VERSION ""

NS_ :

BS_:

BU_:

BO_ 3221225472 VECTOR__INDEPENDENT_SIG_MSG: 0 Vector__XXX
 SG_ FL_brake_temperature : 0|16@1+ (1,0) [0|0] "" Vector__XXX
 SG_ FR_brake_temperature : 16|16@1+ (1,0) [0|0] "" Vector__XXX
 SG_ RL_brake_temperature : 48|16@1+ (1,0) [0|0] "" Vector__XXX
 SG_ RR_brake_temperature : 32|16@1+ (1,0) [0|0] "" Vector__XXX
 SG_ off_grid_power_connection : 24|1@1+ (1,0) [0|0] "" Vector__XXX

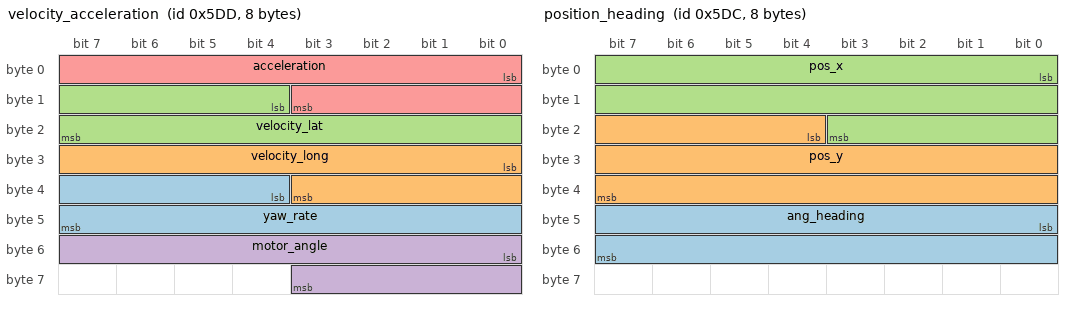
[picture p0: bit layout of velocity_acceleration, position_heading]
BO_ 1501 velocity_acceleration: 8 Vector__XXX
 SG_ yaw_rate : 36|12@1- (0.025,0) [-51.2|51.175] "rps" Vector__XXX
 SG_ velocity_long : 24|12@1- (0.05,0) [-102.4|102.35] "mps" Vector__XXX
 SG_ velocity_lat : 12|12@1- (0.05,0) [-102.4|102.35] "mps" Vector__XXX
 SG_ motor_angle : 48|12@1- (0.5,0) [-255|255] "rad" Vector__XXX
 SG_ acceleration : 0|12@1- (0.025,0) [-51.2|51.175] "mps2" Vector__XXX

BO_ 1500 position_heading: 8 Vector__XXX
 SG_ ang_heading : 40|16@1- (0.01,0) [-327.68|327.67] "rad" Vector__XXX
 SG_ pos_y : 20|20@1- (0.01,0) [-5242.88|5242.87] "m" Vector__XXX
 SG_ pos_x : 0|20@1- (0.01,0) [-5242.88|5242.87] "m" Vector__XXX

BO_ 1403 gear_shift_cmd: 8 Vector__XXX
 SG_ desired_gear : 0|8@1+ (1,0) [0|0] "" Vector__XXX

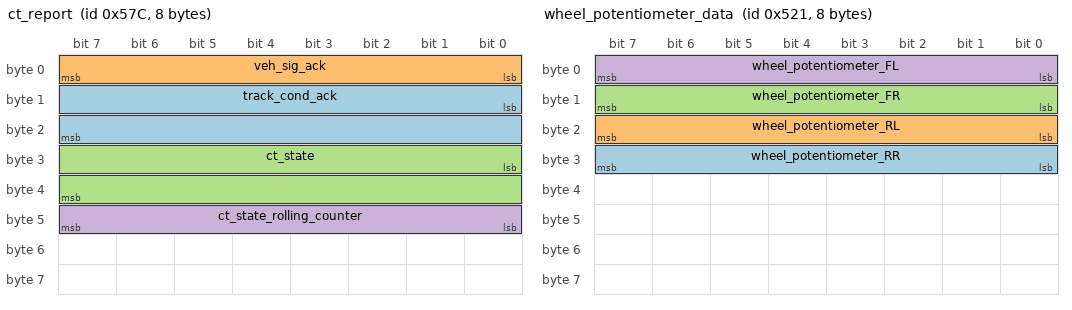
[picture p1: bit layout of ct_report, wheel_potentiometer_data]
BO_ 1404 ct_report: 8 Vector__XXX
 SG_ track_cond_ack : 8|16@1+ (1,0) [0|0] "" Vector__XXX
 SG_ veh_sig_ack : 0|8@1+ (1,0) [0|0] "" Vector__XXX
 SG_ ct_state : 24|16@1+ (1,0) [0|0] "" Vector__XXX
 SG_ ct_state_rolling_counter : 40|8@1+ (1,0) [0|9] "" Vector__XXX

BO_ 1402 steering_cmd: 8 Vector__XXX
 SG_ steering_motor_cmd_counter : 16|8@1+ (1,0) [0|255] "" Vector__XXX
 SG_ steering_motor_ang_cmd : 0|10@1- (0.5,0) [-512|511] "deg" Vector__XXX

BO_ 1401 accelerator_cmd: 8 Vector__XXX
 SG_ acc_pedal_cmd_counter : 16|8@1+ (1,0) [0|255] "" Vector__XXX
 SG_ acc_pedal_cmd : 0|16@1- (0.01,0) [-150|655.35] "%" Vector__XXX

BO_ 1400 brake_pressure_cmd: 8 Vector__XXX
 SG_ brk_pressure_cmd_counter : 16|8@1+ (1,0) [0|255] "" Vector__XXX
 SG_ brake_pressure_cmd : 0|13@1+ (1,0) [0|8191] "" Vector__XXX

BO_ 1313 wheel_potentiometer_data: 8 Vector__XXX
 SG_ wheel_potentiometer_RR : 24|8@1+ (0.2,0) [0|510] "" Vector__XXX
 SG_ wheel_potentiometer_RL : 16|8@1+ (0.2,0) [0|510] "" Vector__XXX
 SG_ wheel_potentiometer_FR : 8|8@1+ (0.2,0) [0|510] "" Vector__XXX
 SG_ wheel_potentiometer_FL : 0|8@1+ (0.2,0) [0|510] "" Vector__XXX

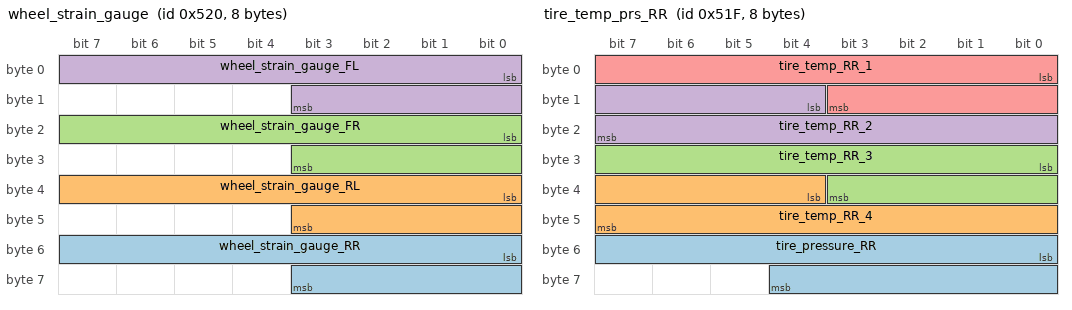
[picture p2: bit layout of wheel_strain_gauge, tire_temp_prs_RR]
BO_ 1312 wheel_strain_gauge: 8 Vector__XXX
 SG_ wheel_strain_gauge_RR : 48|12@1+ (10,0) [0|8190] "" Vector__XXX
 SG_ wheel_strain_gauge_RL : 32|12@1+ (10,0) [0|8190] "" Vector__XXX
 SG_ wheel_strain_gauge_FR : 16|12@1+ (10,0) [0|8190] "" Vector__XXX
 SG_ wheel_strain_gauge_FL : 0|12@1+ (10,0) [0|81900] "" Vector__XXX

BO_ 1311 tire_temp_prs_RR: 8 Vector__XXX
 SG_ tire_pressure_RR : 48|13@1+ (1,0) [0|8191] "C" Vector__XXX
 SG_ tire_temp_RR_4 : 36|12@1+ (0.1,-100) [-100|309.5] "C" Vector__XXX
 SG_ tire_temp_RR_3 : 24|12@1+ (0.1,-100) [-100|309.5] "C" Vector__XXX
 SG_ tire_temp_RR_2 : 12|12@1+ (0.1,-100) [-100|309.5] "C" Vector__XXX
 SG_ tire_temp_RR_1 : 0|12@1+ (0.1,-100) [-100|309.5] "mBar" Vector__XXX

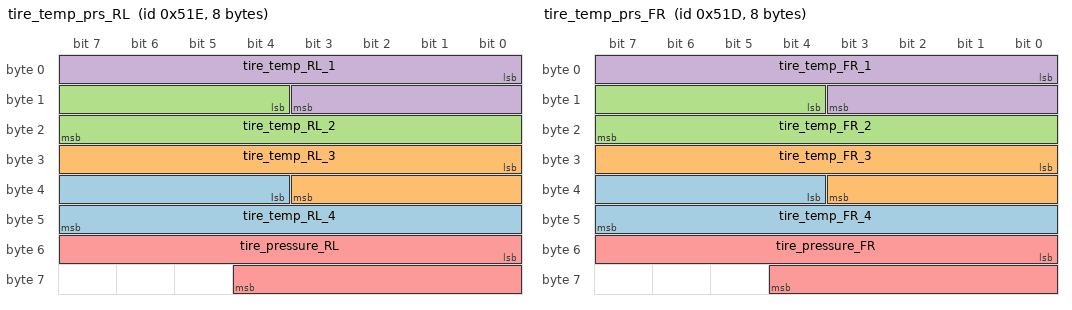
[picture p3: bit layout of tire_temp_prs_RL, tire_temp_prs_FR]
BO_ 1310 tire_temp_prs_RL: 8 Vector__XXX
 SG_ tire_temp_RL_4 : 36|12@1+ (0.1,-100) [-100|309.5] "C" Vector__XXX
 SG_ tire_temp_RL_3 : 24|12@1+ (0.1,-100) [-100|309.5] "C" Vector__XXX
 SG_ tire_temp_RL_2 : 12|12@1+ (0.1,-100) [-100|309.5] "C" Vector__XXX
 SG_ tire_temp_RL_1 : 0|12@1+ (0.1,-100) [-100|309.5] "C" Vector__XXX
 SG_ tire_pressure_RL : 48|13@1+ (1,0) [0|8191] "mBar" Vector__XXX

BO_ 1309 tire_temp_prs_FR: 8 Vector__XXX
 SG_ tire_temp_FR_4 : 36|12@1+ (0.1,-100) [-100|309.5] "C" Vector__XXX
 SG_ tire_temp_FR_3 : 24|12@1+ (0.1,-100) [-100|309.5] "C" Vector__XXX
 SG_ tire_temp_FR_2 : 12|12@1+ (0.1,-100) [-100|309.5] "C" Vector__XXX
 SG_ tire_temp_FR_1 : 0|12@1+ (0.1,-100) [-100|309.5] "C" Vector__XXX
 SG_ tire_pressure_FR : 48|13@1+ (1,0) [0|8191] "mBar" Vector__XXX

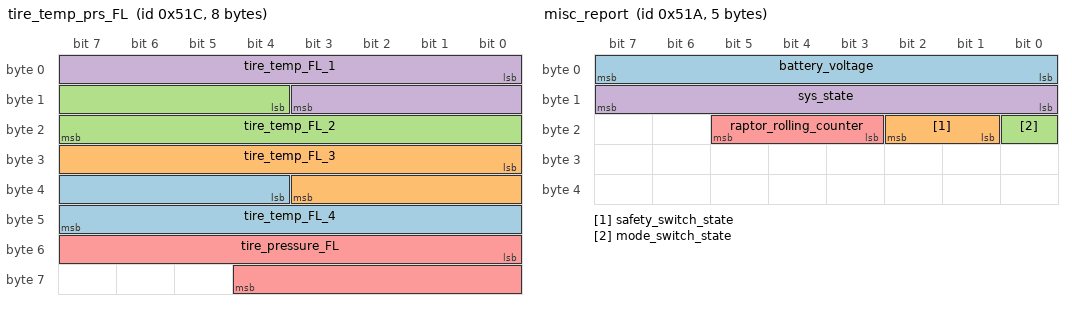
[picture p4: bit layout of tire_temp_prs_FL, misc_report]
BO_ 1308 tire_temp_prs_FL: 8 Vector__XXX
 SG_ tire_temp_FL_4 : 36|12@1+ (0.1,-100) [-100|309.5] "C" Vector__XXX
 SG_ tire_temp_FL_3 : 24|12@1+ (0.1,-100) [-100|309.5] "C" Vector__XXX
 SG_ tire_temp_FL_2 : 12|12@1+ (0.1,-100) [-100|309.5] "C" Vector__XXX
 SG_ tire_temp_FL_1 : 0|12@1+ (0.1,-100) [-100|309.5] "C" Vector__XXX
 SG_ tire_pressure_FL : 48|13@1+ (1,0) [0|8191] "mBar" Vector__XXX

BO_ 1306 misc_report: 5 Vector__XXX
 SG_ battery_voltage : 0|8@1+ (10,0) [0|0] "V" Vector__XXX
 SG_ safety_switch_state : 17|2@1+ (1,0) [0|0] "" Vector__XXX
 SG_ mode_switch_state : 16|1@1+ (1,0) [0|0] "" Vector__XXX
 SG_ sys_state : 8|8@1+ (1,0) [0|0] "" Vector__XXX
 SG_ raptor_rolling_counter : 19|3@1+ (1,0) [0|0] "" Vector__XXX

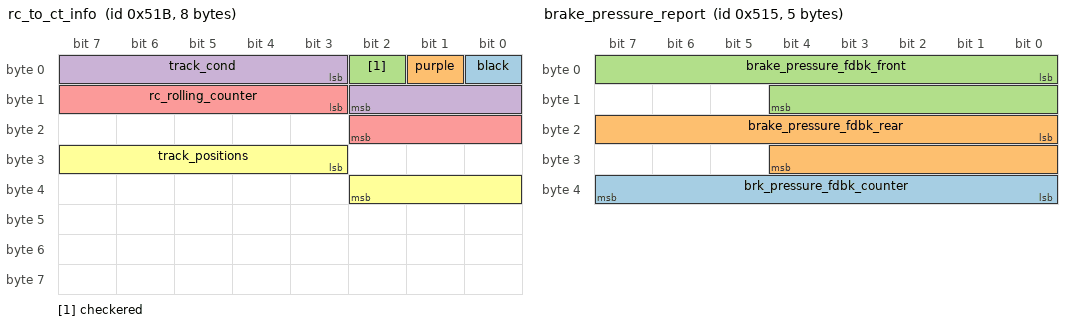
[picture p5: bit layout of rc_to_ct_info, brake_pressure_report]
BO_ 1307 rc_to_ct_info: 8 Vector__XXX
 SG_ black : 0|1@1+ (1,0) [0|0] "" Vector__XXX
 SG_ purple : 1|1@1+ (1,0) [0|0] "" Vector__XXX
 SG_ checkered : 2|1@1+ (1,0) [0|0] "" Vector__XXX
 SG_ track_cond : 3|8@1+ (1,0) [0|0] "" Vector__XXX
 SG_ rc_rolling_counter : 11|8@1+ (1,0) [0|0] "" Vector__XXX
 SG_ track_positions : 27|8@1+ (1,0) [0|0] "" Vector__XXX

BO_ 1303 steering_report: 3 Vector__XXX
 SG_ steering_motor_fdbk_counter : 16|8@1+ (1,0) [0|255] "" Vector__XXX
 SG_ steering_motor_ang_fdbk : 0|10@1- (0.5,0) [-512|511] "deg" Vector__XXX

BO_ 1302 accelerator_report: 3 Vector__XXX
 SG_ acc_pedal_fdbk_counter : 16|8@1+ (1,0) [0|255] "" Vector__XXX
 SG_ acc_pedal_fdbk : 0|16@1+ (1,0) [0|65535] "%" Vector__XXX

BO_ 1301 brake_pressure_report: 5 Vector__XXX
 SG_ brk_pressure_fdbk_counter : 32|8@1+ (1,0) [0|255] "" Vector__XXX
 SG_ brake_pressure_fdbk_rear : 16|13@1+ (1,0) [0|8191] "kPa" Vector__XXX
 SG_ brake_pressure_fdbk_front : 0|13@1+ (1,0) [0|8191] "kPa" Vector__XXX

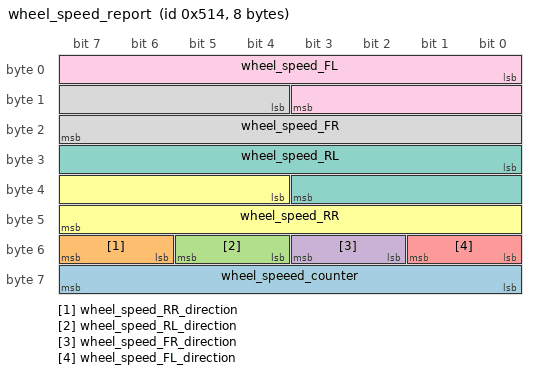
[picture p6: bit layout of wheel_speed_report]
BO_ 1300 wheel_speed_report: 8 Vector__XXX
 SG_ wheel_speeed_counter : 56|8@1+ (1,0) [0|255] "" Vector__XXX
 SG_ wheel_speed_RR_direction : 54|2@1- (1,0) [-1|1] "" Vector__XXX
 SG_ wheel_speed_RL_direction : 52|2@1- (1,0) [-1|1] "" Vector__XXX
 SG_ wheel_speed_FR_direction : 50|2@1- (1,0) [-1|1] "" Vector__XXX
 SG_ wheel_speed_FL_direction : 48|2@1- (1,0) [-1|1] "" Vector__XXX
 SG_ wheel_speed_RR : 36|12@1+ (1,0) [0|4095] "rpm" Vector__XXX
 SG_ wheel_speed_RL : 24|12@1+ (1,0) [0|4095] "rpm" Vector__XXX
 SG_ wheel_speed_FR : 12|12@1+ (1,0) [0|4095] "rpm" Vector__XXX
 SG_ wheel_speed_FL : 0|12@1+ (1,0) [0|4095] "rpm" Vector__XXX

CM_ SG_ 3221225472 off_grid_power_connection "remove it";
CM_ BO_ 1403 "DO12 - gear shift command";
CM_ BO_ 1404 "DO12 - CT report to RC";
CM_ BO_ 1402 "steering demand from computer to raptor in degrees
";
CM_ SG_ 1402 steering_motor_cmd_counter "rolling counter for steering motor angle commamd message";
CM_ SG_ 1402 steering_motor_ang_cmd "motor angle command  in deg.

physical_value = offset + factor * raw_value_decimal";
CM_ SG_ 1401 acc_pedal_cmd "0-100 % accelerator pedal
";
CM_ BO_ 1400 "Demand of brake pressure fron computer to rapter in kPa
";
CM_ SG_ 1400 brk_pressure_cmd_counter "rolling counter for brake pressure command message";
CM_ SG_ 1400 brake_pressure_cmd "Brake pressure for front wheels in kPa. demand from competition team
values should be positive integer in kPa.";
CM_ BO_ 1313 "Contains the information of potnetiometer, strain gage readings and calculated Fz of the front right wheel ";
CM_ SG_ 1313 wheel_potentiometer_RR "potentiometer reading of front left assembly";
CM_ SG_ 1313 wheel_potentiometer_RL "potentiometer reading of front left assembly";
CM_ SG_ 1313 wheel_potentiometer_FR "potentiometer reading of front left assembly";
CM_ SG_ 1313 wheel_potentiometer_FL "potentiometer reading of front left assembly";
CM_ BO_ 1312 "Contains the information of potnetiometer, strain gage readings and calculated Fz of the front left wheel ";
CM_ SG_ 1312 wheel_strain_gauge_RR "strain gauge load value in N rear right wheel  in mm.
";
CM_ SG_ 1312 wheel_strain_gauge_RL "strain gauge load value in N rear left wheel  in mm.
";
CM_ SG_ 1312 wheel_strain_gauge_FR "strain gauge load value in N front right wheel  in mm.
";
CM_ SG_ 1312 wheel_strain_gauge_FL "strain gauge load value in N front left wheel in mm.
";
CM_ BO_ 1311 "temperature and pressure information for front left tire";
CM_ SG_ 1311 tire_pressure_RR "tire pressure in mBar";
CM_ SG_ 1311 tire_temp_RR_4 "tire core temperature data will be in deg.
signal_1 : left portion of tire
signal_2 : middle left portion of tire
signal_3 : middle right portion of tire
signal_4 : right portion of tire
";
CM_ SG_ 1311 tire_temp_RR_3 "tire core temperature data will be in deg.
signal_1 : left portion of tire
signal_2 : middle left portion of tire
signal_3 : middle right portion of tire
signal_4 : right portion of tire
";
CM_ SG_ 1311 tire_temp_RR_2 "tire core temperature data will be in deg.
signal_1 : left portion of tire
signal_2 : middle left portion of tire
signal_3 : middle right portion of tire
signal_4 : right portion of tire
";
CM_ SG_ 1311 tire_temp_RR_1 "tire core temperature data will be in deg.
signal_1 : left portion of tire
signal_2 : middle left portion of tire
signal_3 : middle right portion of tire
signal_4 : right portion of tire
";
CM_ BO_ 1310 "temperature and pressure information for front left tire";
CM_ SG_ 1310 tire_temp_RL_4 "tire core temperature data will be in deg.
signal_1 : left portion of tire
signal_2 : middle left portion of tire
signal_3 : middle right portion of tire
signal_4 : right portion of tire
";
CM_ SG_ 1310 tire_temp_RL_3 "tire core temperature data will be in deg.
signal_1 : left portion of tire
signal_2 : middle left portion of tire
signal_3 : middle right portion of tire
signal_4 : right portion of tire
";
CM_ SG_ 1310 tire_temp_RL_2 "tire core temperature data will be in deg.
signal_1 : left portion of tire
signal_2 : middle left portion of tire
signal_3 : middle right portion of tire
signal_4 : right portion of tire
";
CM_ SG_ 1310 tire_temp_RL_1 "tire core temperature data will be in deg.
signal_1 : left portion of tire
signal_2 : middle left portion of tire
signal_3 : middle right portion of tire
signal_4 : right portion of tire
";
CM_ SG_ 1310 tire_pressure_RL "tire pressure in mBar";
CM_ BO_ 1309 "temperature and pressure information for front left tire";
CM_ SG_ 1309 tire_temp_FR_4 "tire core temperature data will be in deg.
signal_1 : left portion of tire
signal_2 : middle left portion of tire
signal_3 : middle right portion of tire
signal_4 : right portion of tire
";
CM_ SG_ 1309 tire_temp_FR_3 "tire core temperature data will be in deg.
signal_1 : left portion of tire
signal_2 : middle left portion of tire
signal_3 : middle right portion of tire
signal_4 : right portion of tire
";
CM_ SG_ 1309 tire_temp_FR_2 "tire core temperature data will be in deg.
signal_1 : left portion of tire
signal_2 : middle left portion of tire
signal_3 : middle right portion of tire
signal_4 : right portion of tire
";
CM_ SG_ 1309 tire_temp_FR_1 "tire core temperature data will be in deg.
signal_1 : left portion of tire
signal_2 : middle left portion of tire
signal_3 : middle right portion of tire
signal_4 : right portion of tire
";
CM_ SG_ 1309 tire_pressure_FR "tire pressure in mBar";
CM_ BO_ 1308 "temperature and pressure information for front left tire";
CM_ SG_ 1308 tire_temp_FL_4 "tire core temperature data will be in deg.
signal_1 : left portion of tire
signal_2 : middle left portion of tire
signal_3 : middle right portion of tire
signal_4 : right portion of tire
";
CM_ SG_ 1308 tire_temp_FL_3 "tire core temperature data will be in deg.
signal_1 : left portion of tire
signal_2 : middle left portion of tire
signal_3 : middle right portion of tire
signal_4 : right portion of tire
";
CM_ SG_ 1308 tire_temp_FL_2 "tire core temperature data will be in deg.
signal_1 : left portion of tire
signal_2 : middle left portion of tire
signal_3 : middle right portion of tire
signal_4 : right portion of tire
";
CM_ SG_ 1308 tire_temp_FL_1 "tire core temperature data will be in deg.
signal_1 : left portion of tire
signal_2 : middle left portion of tire
signal_3 : middle right portion of tire
signal_4 : right portion of tire
";
CM_ SG_ 1308 tire_pressure_FL "tire pressure in mBar";
CM_ BO_ 1306 "DO12 - misc report";
CM_ BO_ 1307 "TODO: Needs to be changed, inconsistent
";
CM_ SG_ 1303 steering_motor_fdbk_counter "rolling counter for steering motor angle feedbak message";
CM_ SG_ 1303 steering_motor_ang_fdbk "motor angle feedback in deg.

physical_value = offset + factor * raw_value_decimal";
CM_ BO_ 1301 "Brake pressure for front and rear wheels in kPa. ";
CM_ SG_ 1301 brk_pressure_fdbk_counter "rolling counter for brake pressure feedback message";
CM_ SG_ 1301 brake_pressure_fdbk_rear "Brake pressure for rear wheels in kPa. 
values will be positive integer in kPa.";
CM_ SG_ 1301 brake_pressure_fdbk_front "Brake pressure for front wheels in kPa. 
values will be positive integer in kPa.";
CM_ SG_ 1300 wheel_speeed_counter "rolling counter for wheel speed message";
CM_ SG_ 1300 wheel_speed_RR_direction "wheel speed of rear right:

+1: forward
  0: static
- 1: reverse";
CM_ SG_ 1300 wheel_speed_RL_direction "wheel speed of rear left:

+1: forward
  0: static
- 1: reverse";
CM_ SG_ 1300 wheel_speed_FR_direction "wheel speed of front right:

+1: forward
  0: static
- 1: reverse";
CM_ SG_ 1300 wheel_speed_FL_direction "wheel speed of front left:

+1: forward
  0: static
- 1: reverse";
CM_ SG_ 1300 wheel_speed_RR "rear right wheel speed in rpm";
CM_ SG_ 1300 wheel_speed_RL "rear left wheel speed in rpm";
CM_ SG_ 1300 wheel_speed_FR "front right wheel speed in rpm";
CM_ SG_ 1300 wheel_speed_FL "front left wheel speed in rpm";
BA_DEF_  "BusType" STRING ;
BA_DEF_DEF_  "BusType" "CAN";
